VERSION ""

NS_ :

BS_:

BU_: D2S USER

BO_ 3221225472 VECTOR__INDEPENDENT_SIG_MSG: 0 Vector__XXX
 SG_ Brake_angle : 0|16@1- (1,0) [-10|170] "deg"  USER
 SG_ Lon_Con_EN_lo : 0|1@1+ (1,0) [0|1] ""  USER
 SG_ Lat_Con_En_lo : 4|1@1+ (1,0) [0|1] ""  USER
 SG_ Lat_Over_Mod_lo : 5|1@1+ (1,0) [0|1] ""  USER
 SG_ Steering_CMD_lo : 8|16@1+ (0.1,0) [-500|500] ""  USER
 SG_ Brake_CMD_lo : 24|8@1+ (1,0) [0|255] ""  USER
 SG_ Con_mode : 40|4@1+ (1,0) [0|2] ""  USER
 SG_ Accel_CMD_lo : 32|8@1+ (1,0) [0|255] ""  USER

BO_ 688 Steering_angle: 5 D2S
 SG_ Steering_angle : 0|16@1- (0.1,0) [-500|500] "deg"  USER

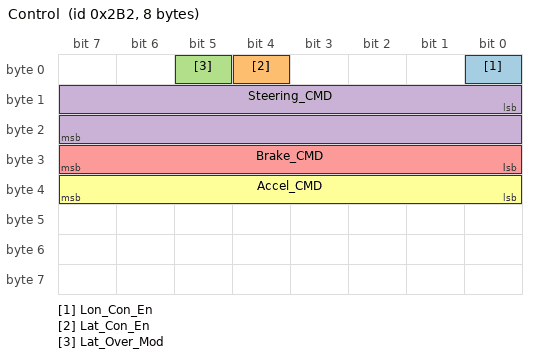
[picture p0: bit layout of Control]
BO_ 690 Control: 8 USER
 SG_ Lon_Con_En : 0|1@1+ (1,0) [0|0] ""  D2S
 SG_ Lat_Con_En : 4|1@1+ (1,0) [0|0] ""  D2S
 SG_ Lat_Over_Mod : 5|1@1+ (1,0) [0|0] ""  D2S
 SG_ Steering_CMD : 8|16@1- (0.1,0) [-500|500] "deg"  D2S
 SG_ Brake_CMD : 24|8@1+ (1,0) [0|255] ""  D2S
 SG_ Accel_CMD : 32|8@1+ (1,0) [0|255] ""  D2S

VAL_ 690 Lon_Con_En 0 "Off" 1 "On" ;
VAL_ 690 Lat_Con_En 0 "Off" 1 "On" ;
VAL_ 690 Lat_Over_Mod 0 "Ignore" 1 "Override" ;
